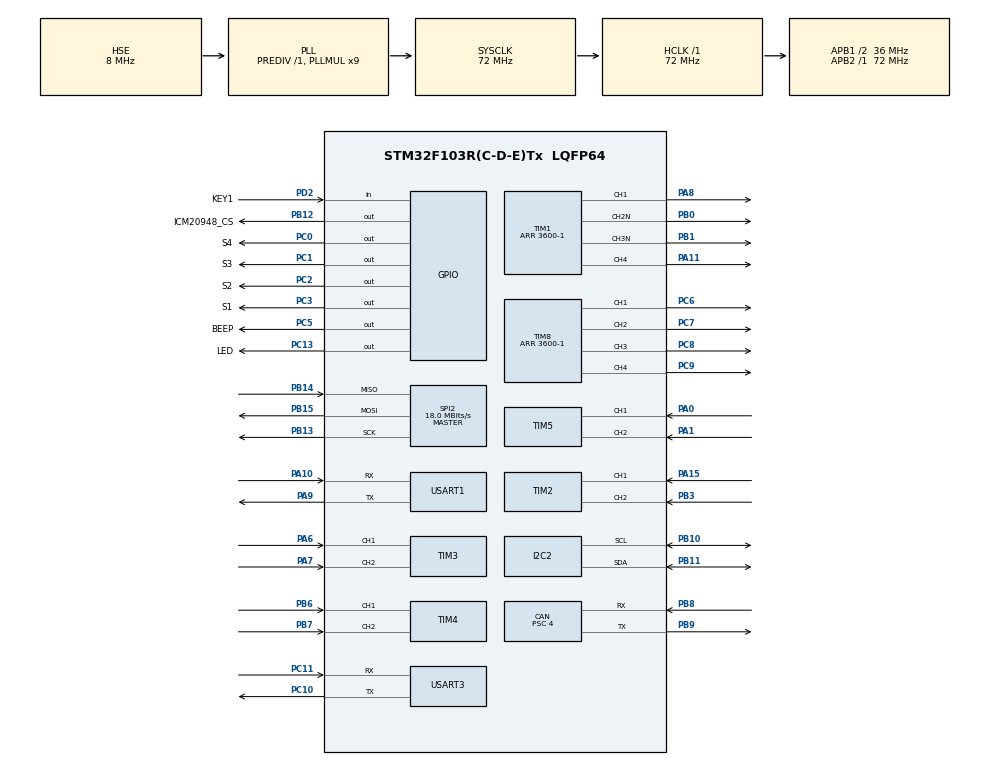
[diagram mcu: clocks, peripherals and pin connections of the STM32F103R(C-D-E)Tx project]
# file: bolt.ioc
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CAN.ABOM=ENABLE
CAN.BS1=CAN_BS1_13TQ
CAN.BS2=CAN_BS2_4TQ
CAN.CalculateBaudRate=500000
CAN.CalculateTimeBit=2000
CAN.CalculateTimeQuantum=111.11111111111111
CAN.Prescaler=4
CAN.RFLM=DISABLE
Dma.Request0=USART1_RX
Dma.Request1=USART3_RX
Dma.USART1_RX.0.Direction=DMA_PERIPH_TO_MEMORY
Dma.USART1_RX.0.Instance=DMA1_Channel5
Dma.USART1_RX.0.MemDataAlignment=DMA_MDATAALIGN_BYTE
Dma.USART1_RX.0.MemInc=DMA_MINC_ENABLE
Dma.USART1_RX.0.Mode=DMA_NORMAL
Dma.USART1_RX.0.PeriphDataAlignment=DMA_PDATAALIGN_BYTE
Dma.USART1_RX.0.PeriphInc=DMA_PINC_DISABLE
Dma.USART1_RX.0.Priority=DMA_PRIORITY_LOW
Dma.USART3_RX.1.Direction=DMA_PERIPH_TO_MEMORY
Dma.USART3_RX.1.Instance=DMA1_Channel3
Dma.USART3_RX.1.MemDataAlignment=DMA_MDATAALIGN_BYTE
Dma.USART3_RX.1.MemInc=DMA_MINC_ENABLE
Dma.USART3_RX.1.Mode=DMA_NORMAL
Dma.USART3_RX.1.PeriphDataAlignment=DMA_PDATAALIGN_BYTE
Dma.USART3_RX.1.PeriphInc=DMA_PINC_DISABLE
Dma.USART3_RX.1.Priority=DMA_PRIORITY_LOW
FREERTOS.Tasks01=ledTask,24,128,vLed_Task,As weak,NULL,Dynamic,NULL,NULL;commandTask,24,192,vCommand_Task,As weak,NULL,Dynamic,NULL,NULL;queryTask,24,192,vQuery_Task,As weak,NULL,Dynamic,NULL,NULL;processTask,24,384,vProcess_Task,As weak,NULL,Dynamic,NULL,NULL;processTaskv2,24,256,v2Process_Task,As weak,NULL,Dynamic,NULL,NULL
FREERTOS.configTOTAL_HEAP_SIZE=9000
FREERTOS.configUSE_NEWLIB_REENTRANT=1
Mcu.Family=STM32F1
Mcu.Name=STM32F103R(C-D-E)Tx
Mcu.Package=LQFP64
NVIC.CAN1_RX1_IRQn=true\:5\:0\:false\:false\:true\:true\:true\:true\:true
NVIC.CAN1_SCE_IRQn=true\:5\:0\:false\:false\:true\:true\:true\:true\:true
NVIC.DMA1_Channel3_IRQn=true\:5\:0\:false\:false\:true\:true\:false\:true\:true
NVIC.DMA1_Channel5_IRQn=true\:5\:0\:false\:false\:true\:true\:false\:true\:true
NVIC.PriorityGroup=NVIC_PRIORITYGROUP_4
NVIC.TIM6_IRQn=true\:15\:0\:false\:false\:true\:false\:false\:true\:true
NVIC.TIM7_IRQn=true\:5\:0\:false\:false\:true\:true\:true\:true\:true
NVIC.TimeBase=TIM6_IRQn
NVIC.TimeBaseIP=TIM6
NVIC.USART1_IRQn=true\:5\:0\:false\:false\:true\:true\:true\:true\:true
NVIC.USART3_IRQn=true\:5\:0\:false\:false\:true\:true\:true\:true\:true
NVIC.USB_HP_CAN1_TX_IRQn=true\:5\:0\:false\:false\:true\:true\:true\:true\:true
NVIC.USB_LP_CAN1_RX0_IRQn=true\:5\:0\:false\:false\:true\:true\:true\:true\:true
PA0-WKUP.Signal=S_TIM5_CH1
PA1.Signal=S_TIM5_CH2
PA10.GPIO_Mode=GPIO_MODE_INPUT
PA10.GPIO_PuPd=GPIO_NOPULL
PA10.Mode=Asynchronous
PA10.Signal=USART1_RX
PA11.Signal=S_TIM1_CH4
PA13.Mode=Serial_Wire
PA13.Signal=SYS_JTMS-SWDIO
PA14.Mode=Serial_Wire
PA14.Signal=SYS_JTCK-SWCLK
PA15.Signal=S_TIM2_CH1_ETR
PA6.Signal=S_TIM3_CH1
PA7.Signal=S_TIM3_CH2
PA8.Signal=S_TIM1_CH1
PA9.GPIO_Speed=GPIO_SPEED_FREQ_HIGH
PA9.Mode=Asynchronous
PA9.Signal=USART1_TX
PB0.Mode=PWM Generation2 CH2N
PB0.Signal=TIM1_CH2N
PB1.Mode=PWM Generation3 CH3N
PB1.Signal=TIM1_CH3N
PB10.Mode=I2C
PB10.Signal=I2C2_SCL
PB11.Mode=I2C
PB11.Signal=I2C2_SDA
PB12.GPIO_Label=ICM20948_CS
PB12.Signal=GPIO_Output
PB13.Mode=Full_Duplex_Master
PB13.Signal=SPI2_SCK
PB14.Mode=Full_Duplex_Master
PB14.Signal=SPI2_MISO
PB15.Mode=Full_Duplex_Master
PB15.Signal=SPI2_MOSI
PB3.Signal=S_TIM2_CH2
PB6.Signal=S_TIM4_CH1
PB7.Signal=S_TIM4_CH2
PB8.Mode=CAN_Activate
PB8.Signal=CAN_RX
PB9.Mode=CAN_Activate
PB9.Signal=CAN_TX
PC0.GPIO_Label=S4
PC0.GPIO_ModeDefaultOutputPP=GPIO_MODE_OUTPUT_PP
PC0.GPIO_PuPd=GPIO_NOPULL
PC0.GPIO_Speed=GPIO_SPEED_FREQ_HIGH
PC0.PinState=GPIO_PIN_RESET
PC0.Signal=GPIO_Output
PC1.GPIO_Label=S3
PC1.GPIO_ModeDefaultOutputPP=GPIO_MODE_OUTPUT_PP
PC1.GPIO_PuPd=GPIO_NOPULL
PC1.GPIO_Speed=GPIO_SPEED_FREQ_HIGH
PC1.PinState=GPIO_PIN_RESET
PC1.Signal=GPIO_Output
PC10.Mode=Asynchronous
PC10.Signal=USART3_TX
PC11.Mode=Asynchronous
PC11.Signal=USART3_RX
PC13-TAMPER-RTC.GPIO_Label=LED
PC13-TAMPER-RTC.Signal=GPIO_Output
PC2.GPIO_Label=S2
PC2.GPIO_ModeDefaultOutputPP=GPIO_MODE_OUTPUT_PP
PC2.GPIO_PuPd=GPIO_NOPULL
PC2.GPIO_Speed=GPIO_SPEED_FREQ_HIGH
PC2.PinState=GPIO_PIN_RESET
PC2.Signal=GPIO_Output
PC3.GPIO_Label=S1
PC3.GPIO_ModeDefaultOutputPP=GPIO_MODE_OUTPUT_PP
PC3.GPIO_PuPd=GPIO_NOPULL
PC3.GPIO_Speed=GPIO_SPEED_FREQ_HIGH
PC3.PinState=GPIO_PIN_RESET
PC3.Signal=GPIO_Output
PC5.GPIO_Label=BEEP
PC5.Signal=GPIO_Output
PC6.Signal=S_TIM8_CH1
PC7.Signal=S_TIM8_CH2
PC8.Signal=S_TIM8_CH3
PC9.Signal=S_TIM8_CH4
PD0-OSC_IN.Mode=HSE-External-Oscillator
PD0-OSC_IN.Signal=RCC_OSC_IN
PD1-OSC_OUT.Mode=HSE-External-Oscillator
PD1-OSC_OUT.Signal=RCC_OSC_OUT
PD2.GPIO_Label=KEY1
PD2.Signal=GPIO_Input
ProjectManager.HeapSize=0x200
ProjectManager.StackSize=0x400
ProjectManager.TargetToolchain=CMake
RCC.AHBFreq_Value=72000000
RCC.APB1CLKDivider=RCC_HCLK_DIV2
RCC.APB1Freq_Value=36000000
RCC.APB1TimFreq_Value=72000000
RCC.APB2Freq_Value=72000000
RCC.APB2TimFreq_Value=72000000
RCC.HCLKFreq_Value=72000000
RCC.HSE_Timout=250
RCC.PLLMUL=RCC_PLL_MUL9
RCC.PLLSourceVirtual=RCC_PLLSOURCE_HSE
RCC.PREFETCH_ENABLE=1
RCC.SYSCLKFreq_VALUE=72000000
RCC.SYSCLKSource=RCC_SYSCLKSOURCE_PLLCLK
RCC.USBFreq_Value=72000000
SH.S_TIM1_CH1.0=TIM1_CH1,PWM Generation1 CH1
SH.S_TIM1_CH4.0=TIM1_CH4,PWM Generation4 CH4
SH.S_TIM2_CH1_ETR.0=TIM2_CH1,Encoder_Interface
SH.S_TIM2_CH2.0=TIM2_CH2,Encoder_Interface
SH.S_TIM3_CH1.0=TIM3_CH1,Encoder_Interface
SH.S_TIM3_CH2.0=TIM3_CH2,Encoder_Interface
SH.S_TIM4_CH1.0=TIM4_CH1,Encoder_Interface
SH.S_TIM4_CH2.0=TIM4_CH2,Encoder_Interface
SH.S_TIM5_CH1.0=TIM5_CH1,Encoder_Interface
SH.S_TIM5_CH2.0=TIM5_CH2,Encoder_Interface
SH.S_TIM8_CH1.0=TIM8_CH1,PWM Generation1 CH1
SH.S_TIM8_CH2.0=TIM8_CH2,PWM Generation2 CH2
SH.S_TIM8_CH3.0=TIM8_CH3,PWM Generation3 CH3
SH.S_TIM8_CH4.0=TIM8_CH4,PWM Generation4 CH4
SPI2.BaudRatePrescaler=SPI_BAUDRATEPRESCALER_2
SPI2.CLKPhase=SPI_PHASE_1EDGE
SPI2.CLKPolarity=SPI_POLARITY_LOW
SPI2.CalculateBaudRate=18.0 MBits/s
SPI2.Direction=SPI_DIRECTION_2LINES
SPI2.Mode=SPI_MODE_MASTER
SPI2.VirtualType=VM_MASTER
TIM1.AutoReloadPreload=TIM_AUTORELOAD_PRELOAD_ENABLE
TIM1.Channel-PWM\ Generation1\ CH1=TIM_CHANNEL_1
TIM1.Channel-PWM\ Generation2\ CH2N=TIM_CHANNEL_2
TIM1.Channel-PWM\ Generation3\ CH3N=TIM_CHANNEL_3
TIM1.Channel-PWM\ Generation4\ CH4=TIM_CHANNEL_4
TIM1.Period=3600-1
TIM2.EncoderMode=TIM_ENCODERMODE_TI12
TIM3.EncoderMode=TIM_ENCODERMODE_TI12
TIM4.EncoderMode=TIM_ENCODERMODE_TI12
TIM5.EncoderMode=TIM_ENCODERMODE_TI12
TIM7.AutoReloadPreload=TIM_AUTORELOAD_PRELOAD_DISABLE
TIM7.Period=19999
TIM7.Prescaler=71
TIM8.AutoReloadPreload=TIM_AUTORELOAD_PRELOAD_ENABLE
TIM8.Channel-PWM\ Generation1\ CH1=TIM_CHANNEL_1
TIM8.Channel-PWM\ Generation2\ CH2=TIM_CHANNEL_2
TIM8.Channel-PWM\ Generation3\ CH3=TIM_CHANNEL_3
TIM8.Channel-PWM\ Generation4\ CH4=TIM_CHANNEL_4
TIM8.Period=3600-1
USART1.VirtualMode=VM_ASYNC
USART3.VirtualMode=VM_ASYNC
VP_FREERTOS_VS_CMSIS_V2.Mode=CMSIS_V2
VP_SYS_VS_tim6.Mode=TIM6
VP_TIM1_VS_ClockSourceINT.Mode=Internal
VP_TIM7_VS_ClockSourceINT.Mode=Enable_Timer
VP_TIM8_VS_ClockSourceINT.Mode=Internal
board=custom

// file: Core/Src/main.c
/* USER CODE BEGIN Header */
/**
 ******************************************************************************
 * @file           : main.c
 * @brief          : Main program body
 ******************************************************************************
 * @attention
 *
 * Copyright (c) 2025 STMicroelectronics.
 * All rights reserved.
 *
 * This software is licensed under terms that can be found in the LICENSE file
 * in the root directory of this software component.
 * If no LICENSE file comes with this software, it is provided AS-IS.
 *
 ******************************************************************************
 */
/* USER CODE END Header */
#include "main.h"
#include "cmsis_os.h"
#include "can.h"
#include "dma.h"
#include "i2c.h"
#include "spi.h"
#include "tim.h"
#include "usart.h"
#include "gpio.h"

/* USER CODE BEGIN PV */
void AppPeripheralsInit();
void AppQueuesInit();
/* USER CODE END PV */

void SystemClock_Config(void);
void MX_FREERTOS_Init(void);

int main(void)
{

  /* MCU Configuration--------------------------------------------------------*/

  /* Reset of all peripherals, Initializes the Flash interface and the Systick. */
  HAL_Init();

  /* Configure the system clock */
  SystemClock_Config();

  /* Initialize all configured peripherals */
  MX_GPIO_Init();
  MX_DMA_Init();
  MX_USART1_UART_Init();
  MX_TIM1_Init();
  MX_TIM2_Init();
  MX_TIM7_Init();
  MX_TIM8_Init();
  MX_TIM3_Init();
  MX_TIM4_Init();
  MX_TIM5_Init();
  MX_USART3_UART_Init();
  MX_SPI2_Init();
  MX_CAN_Init();
  MX_I2C2_Init();
  /* USER CODE BEGIN 2 */
  AppPeripheralsInit();
  AppQueuesInit();
  /* USER CODE END 2 */

  /* Init scheduler */
  osKernelInitialize();

  /* Call init function for freertos objects (in cmsis_os2.c) */
  MX_FREERTOS_Init();

  /* Start scheduler */
  osKernelStart();

  /* We should never get here as control is now taken by the scheduler */

  /* Infinite loop */
  while (1)
  {

  }
}

void SystemClock_Config(void)
{
  RCC_OscInitTypeDef RCC_OscInitStruct = {0};
  RCC_ClkInitTypeDef RCC_ClkInitStruct = {0};

  /** Initializes the RCC Oscillators according to the specified parameters
  * in the RCC_OscInitTypeDef structure.
  */
  RCC_OscInitStruct.OscillatorType = RCC_OSCILLATORTYPE_HSE;
  RCC_OscInitStruct.HSEState = RCC_HSE_ON;
  RCC_OscInitStruct.HSEPredivValue = RCC_HSE_PREDIV_DIV1;
  RCC_OscInitStruct.HSIState = RCC_HSI_ON;
  RCC_OscInitStruct.PLL.PLLState = RCC_PLL_ON;
  RCC_OscInitStruct.PLL.PLLSource = RCC_PLLSOURCE_HSE;
  RCC_OscInitStruct.PLL.PLLMUL = RCC_PLL_MUL9;
  if (HAL_RCC_OscConfig(&RCC_OscInitStruct) != HAL_OK)
  {
    Error_Handler();
  }

  /** Initializes the CPU, AHB and APB buses clocks
  */
  RCC_ClkInitStruct.ClockType = RCC_CLOCKTYPE_HCLK|RCC_CLOCKTYPE_SYSCLK
                              |RCC_CLOCKTYPE_PCLK1|RCC_CLOCKTYPE_PCLK2;
  RCC_ClkInitStruct.SYSCLKSource = RCC_SYSCLKSOURCE_PLLCLK;
  RCC_ClkInitStruct.AHBCLKDivider = RCC_SYSCLK_DIV1;
  RCC_ClkInitStruct.APB1CLKDivider = RCC_HCLK_DIV2;
  RCC_ClkInitStruct.APB2CLKDivider = RCC_HCLK_DIV1;

  if (HAL_RCC_ClockConfig(&RCC_ClkInitStruct, FLASH_LATENCY_2) != HAL_OK)
  {
    Error_Handler();
  }
}

void HAL_TIM_PeriodElapsedCallback(TIM_HandleTypeDef *htim)
{
  if (htim->Instance == TIM6)
  {
    HAL_IncTick();
  }
}

void Error_Handler(void)
{
  __disable_irq();
  while (1)
  {
  }
}

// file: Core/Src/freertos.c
/* USER CODE BEGIN Header */
/**
 ******************************************************************************
 * File Name          : freertos.c
 * Description        : Code for freertos applications
 ******************************************************************************
 * @attention
 *
 * Copyright (c) 2025 STMicroelectronics.
 * All rights reserved.
 *
 * This software is licensed under terms that can be found in the LICENSE file
 * in the root directory of this software component.
 * If no LICENSE file comes with this software, it is provided AS-IS.
 *
 ******************************************************************************
 */
/* USER CODE END Header */

#include "FreeRTOS.h"
#include "task.h"
#include "main.h"
#include "cmsis_os.h"

/* Definitions for ledTask */
osThreadId_t ledTaskHandle;
const osThreadAttr_t ledTask_attributes = {
  .name = "ledTask",
  .stack_size = 128 * 4,
  .priority = (osPriority_t) osPriorityNormal,
};
/* Definitions for commandTask */
osThreadId_t commandTaskHandle;
const osThreadAttr_t commandTask_attributes = {
  .name = "commandTask",
  .stack_size = 192 * 4,
  .priority = (osPriority_t) osPriorityNormal,
};
/* Definitions for queryTask */
osThreadId_t queryTaskHandle;
const osThreadAttr_t queryTask_attributes = {
  .name = "queryTask",
  .stack_size = 192 * 4,
  .priority = (osPriority_t) osPriorityNormal,
};
/* Definitions for processTask */
osThreadId_t processTaskHandle;
const osThreadAttr_t processTask_attributes = {
  .name = "processTask",
  .stack_size = 384 * 4,
  .priority = (osPriority_t) osPriorityNormal,
};
/* Definitions for processTaskv2 */
osThreadId_t processTaskv2Handle;
const osThreadAttr_t processTaskv2_attributes = {
  .name = "processTaskv2",
  .stack_size = 256 * 4,
  .priority = (osPriority_t) osPriorityNormal,
};

void vLed_Task(void *argument);
void vCommand_Task(void *argument);
void vQuery_Task(void *argument);
void vProcess_Task(void *argument);
void v2Process_Task(void *argument);

void MX_FREERTOS_Init(void); /* (MISRA C 2004 rule 8.1) */

void MX_FREERTOS_Init(void) {

  /* Create the thread(s) */
  /* creation of ledTask */
  ledTaskHandle = osThreadNew(vLed_Task, NULL, &ledTask_attributes);

  /* creation of commandTask */
  commandTaskHandle = osThreadNew(vCommand_Task, NULL, &commandTask_attributes);

  /* creation of queryTask */
  queryTaskHandle = osThreadNew(vQuery_Task, NULL, &queryTask_attributes);

  /* creation of processTask */
  processTaskHandle = osThreadNew(vProcess_Task, NULL, &processTask_attributes);

  /* creation of processTaskv2 */
  processTaskv2Handle = osThreadNew(v2Process_Task, NULL, &processTaskv2_attributes);

}

__weak void vLed_Task(void *argument)
{
  for (;;)
  {
    osDelay(1);
  }
}

__weak void vCommand_Task(void *argument)
{
  for(;;)
  {
    osDelay(1);
  }
}

__weak void vQuery_Task(void *argument)
{
  for(;;)
  {
    osDelay(1);
  }
}

__weak void vProcess_Task(void *argument)
{
  for(;;)
  {
    osDelay(1);
  }
}

__weak void v2Process_Task(void *argument)
{
  for(;;)
  {
    osDelay(1);
  }
}
